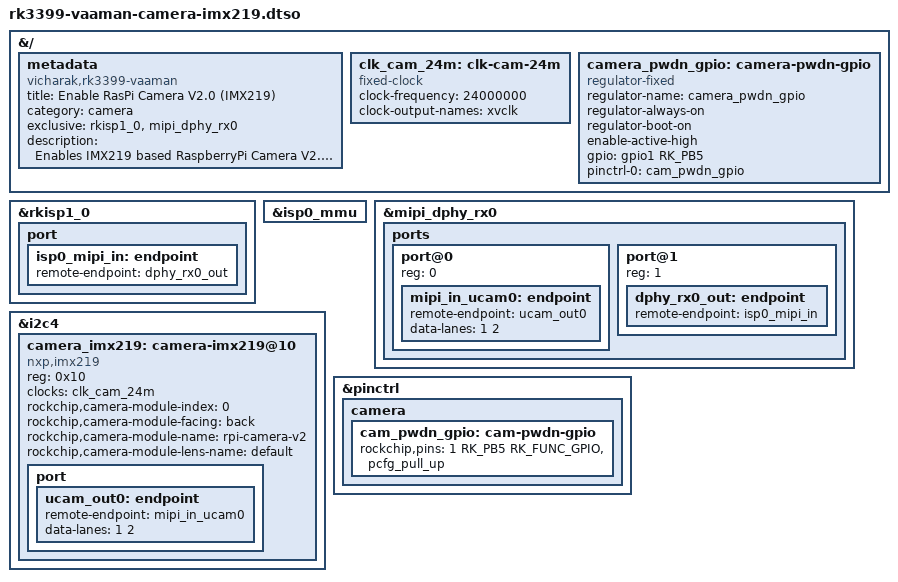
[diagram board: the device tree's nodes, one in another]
// SPDX-License-Identifier: GPL-2.0+
// Copyright (C) 2023 Vicharak Computers LLP

/dts-v1/;
/plugin/;

#include <dt-bindings/gpio/gpio.h>
#include <dt-bindings/pinctrl/rockchip.h>

&{/} {
	metadata {
		title = "Enable RasPi Camera V2.0 (IMX219)";
		compatible = "vicharak,rk3399-vaaman", "rockchip,rk3399";
		category = "camera";
		exclusive = "rkisp1_0", "mipi_dphy_rx0";
		description = "Enables IMX219 based RaspberryPi Camera V2.0 on\nVicharak Vaaman at I2C 4 bus address 10";
	};

	clk_cam_24m: clk-cam-24m {
		compatible = "fixed-clock";
		clock-frequency = <24000000>;
		clock-output-names = "xvclk";
		#clock-cells = <0>;
		status = "okay";
	};

	camera_pwdn_gpio: camera-pwdn-gpio {
		status = "okay";
		compatible = "regulator-fixed";
		regulator-name = "camera_pwdn_gpio";
		regulator-always-on;
		regulator-boot-on;
		enable-active-high;
		gpio = <&gpio1 RK_PB5 GPIO_ACTIVE_HIGH>;
		pinctrl-names = "default";
		pinctrl-0 = <&cam_pwdn_gpio>;
	};
};

&rkisp1_0 {
	status = "okay";

	port {
		isp0_mipi_in: endpoint {
			remote-endpoint = <&dphy_rx0_out>;
		};
	};
};

&isp0_mmu {
	status = "okay";
};

&mipi_dphy_rx0 {
	status = "okay";

	ports {
		#address-cells = <1>;
		#size-cells = <0>;

		port@0 {
			reg = <0>;

			mipi_in_ucam0: endpoint {
				remote-endpoint = <&ucam_out0>;
				data-lanes = <1 2>;
			};
		};

		port@1 {
			reg = <1>;

			dphy_rx0_out: endpoint {
				remote-endpoint = <&isp0_mipi_in>;
			};
		};
	};
};

&i2c4 {
	status = "okay";
	#address-cells = <1>;
	#size-cells = <0>;

	camera_imx219: camera-imx219@10 {
		status = "okay";
		compatible = "nxp,imx219";
		reg = <0x10>;
		clocks = <&clk_cam_24m>;
		clock-names = "xvclk";
		rockchip,camera-module-index = <0>;
		rockchip,camera-module-facing = "back";
		rockchip,camera-module-name = "rpi-camera-v2";
		rockchip,camera-module-lens-name = "default";

		port {
			ucam_out0: endpoint {
				remote-endpoint = <&mipi_in_ucam0>;
				data-lanes = <1 2>;
			};
		};
	};
};

&pinctrl {
	camera {
		cam_pwdn_gpio: cam-pwdn-gpio {
			rockchip,pins =
				<1 RK_PB5 RK_FUNC_GPIO &pcfg_pull_up>;
		};
	};
};
